# ESP32-C5-LP register map
Vendor: ESPRESSIF SYSTEMS (SHANGHAI) CO., LTD.; Series: ESP32 C-Series; File version: 1
CPU: RV32IMAC r0p0, little endian, no MPU, no FPU, 0 interrupt priority bits
Address unit: 32 bits
Registers are 32-bit, read-write, reset 0x0 unless marked. A register's access mark holds for its fields unless they carry their own. Offsets are from the block's base; [hi:lo] are bit positions.

## LP_I2C0 — Low-power I2C (Inter-Integrated Circuit) Controller 0
Base 0x600B1800
0x00 I2C_SCL_LOW_PERIOD — Configures the low level width of the SCL Clock
  [8:0] I2C_SCL_LOW_PERIOD — This register is used to configure for how long SCL remains low in master mode, in I2C module clock cycles.
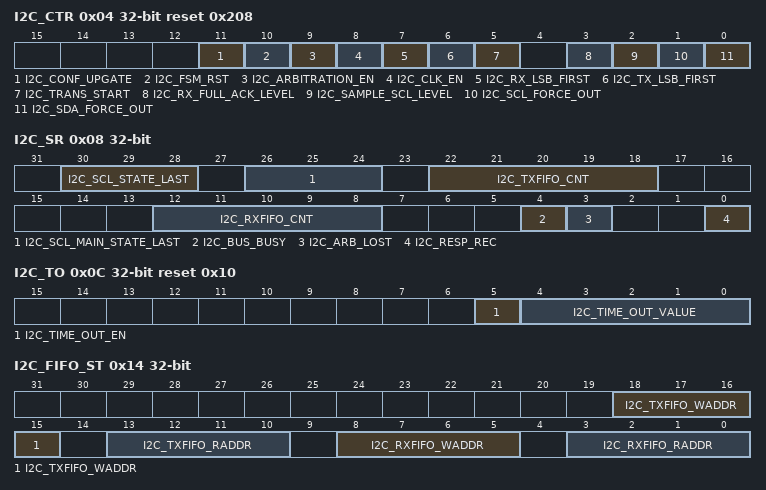
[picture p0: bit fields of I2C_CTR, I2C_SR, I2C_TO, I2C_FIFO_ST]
0x04 I2C_CTR access per field reset 0x208 — Transmission setting
  [11] I2C_CONF_UPGATE wo — synchronization bit
  [10] I2C_FSM_RST wo — This register is used to reset the scl FMS.
  [9] I2C_ARBITRATION_EN rw — This is the enable bit for arbitration_lost.
  [8] I2C_CLK_EN rw — Reserved
  [7] I2C_RX_LSB_FIRST rw — This bit is used to control the storage mode for received data.1: receive data from the least significant bit,0: receive data from the most significant bit.
  [6] I2C_TX_LSB_FIRST rw — This bit is used to control the sending mode for data needing to be sent. 1: send data from the least significant bit,0: send data from the most significant bit.
  [5] I2C_TRANS_START wo — Set this bit to start sending the data in txfifo.
  [3] I2C_RX_FULL_ACK_LEVEL rw — This register is used to configure the ACK value that need to sent by master when the rx_fifo_cnt has reached the threshold.
  [2] I2C_SAMPLE_SCL_LEVEL rw — This register is used to select the sample mode.1: sample SDA data on the SCL low level.0: sample SDA data on the SCL high level.
  [1] I2C_SCL_FORCE_OUT rw — 1: direct output, 0: open drain output.
  [0] I2C_SDA_FORCE_OUT rw — 1: direct output, 0: open drain output.
0x08 I2C_SR ro — Describe I2C work status.
  [30:28] I2C_SCL_STATE_LAST — This field indicates the states of the state machine used to produce SCL.0: Idle, 1: Start, 2: Negative edge, 3: Low, 4: Positive edge, 5: High, 6: Stop
  [26:24] I2C_SCL_MAIN_STATE_LAST — This field indicates the states of the I2C module state machine. 0: Idle, 1: Address shift, 2: ACK address, 3: Rx data, 4: Tx data, 5: Send ACK, 6: Wait ACK
  [22:18] I2C_TXFIFO_CNT — This field stores the amount of received data in RAM.
  [12:8] I2C_RXFIFO_CNT — This field represents the amount of data needed to be sent.
  [4] I2C_BUS_BUSY — 1: the I2C bus is busy transferring data, 0: the I2C bus is in idle state.
  [3] I2C_ARB_LOST — When the I2C controller loses control of SCL line, this register changes to 1.
  [0] I2C_RESP_REC — The received ACK value in master mode or slave mode. 0: ACK, 1: NACK.
0x0C I2C_TO reset 0x10 — Setting time out control for receiving data.
  [5] I2C_TIME_OUT_EN — This is the enable bit for time out control.
  [4:0] I2C_TIME_OUT_VALUE — This register is used to configure the timeout for receiving a data bit in APBclock cycles.
0x14 I2C_FIFO_ST ro — FIFO status register.
  [18:15] I2C_TXFIFO_WADDR — This is the offset address of APB bus writing to txfifo.
  [13:10] I2C_TXFIFO_RADDR — This is the offset address of i2c module reading from txfifo.
  [8:5] I2C_RXFIFO_WADDR — This is the offset address of i2c module receiving data and writing to rxfifo.
  [3:0] I2C_RXFIFO_RADDR — This is the offset address of the APB reading from rxfifo
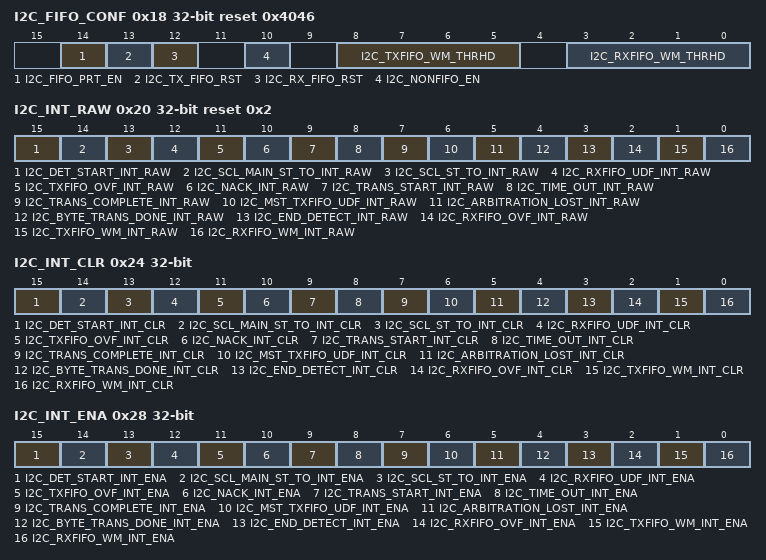
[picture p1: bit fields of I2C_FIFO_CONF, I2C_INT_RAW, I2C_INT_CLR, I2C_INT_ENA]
0x18 I2C_FIFO_CONF reset 0x4046 — FIFO configuration register.
  [14] I2C_FIFO_PRT_EN — The control enable bit of FIFO pointer in non-fifo access mode. This bit controls the valid bits and the interrupts of tx/rx_fifo overflow, underflow, full and empty.
  [13] I2C_TX_FIFO_RST — Set this bit to reset tx-fifo.
  [12] I2C_RX_FIFO_RST — Set this bit to reset rx-fifo.
  [10] I2C_NONFIFO_EN — Set this bit to enable APB nonfifo access.
  [8:5] I2C_TXFIFO_WM_THRHD — The water mark threshold of tx FIFO in nonfifo access mode. When reg_reg_fifo_prt_en is 1 and tx FIFO counter is smaller than reg_txfifo_wm_thrhd[3:0], reg_txfifo_wm_int_raw bit will be valid.
  [3:0] I2C_RXFIFO_WM_THRHD — The water mark threshold of rx FIFO in nonfifo access mode. When reg_reg_fifo_prt_en is 1 and rx FIFO counter is bigger than reg_rxfifo_wm_thrhd[3:0], reg_rxfifo_wm_int_raw bit will be valid.
0x1C I2C_DATA ro — Rx FIFO read data.
  [7:0] I2C_FIFO_RDATA — The value of rx FIFO read data.
0x20 I2C_INT_RAW ro reset 0x2 — Raw interrupt status
  [15] I2C_DET_START_INT_RAW — The raw interrupt bit for I2C_DET_START_INT interrupt.
  [14] I2C_SCL_MAIN_ST_TO_INT_RAW — The raw interrupt bit for I2C_SCL_MAIN_ST_TO_INT interrupt.
  [13] I2C_SCL_ST_TO_INT_RAW — The raw interrupt bit for I2C_SCL_ST_TO_INT interrupt.
  [12] I2C_RXFIFO_UDF_INT_RAW — The raw interrupt bit for I2C_RXFIFO_UDF_INT interrupt.
  [11] I2C_TXFIFO_OVF_INT_RAW — The raw interrupt bit for I2C_TXFIFO_OVF_INT interrupt.
  [10] I2C_NACK_INT_RAW — The raw interrupt bit for I2C_SLAVE_STRETCH_INT interrupt.
  [9] I2C_TRANS_START_INT_RAW — The raw interrupt bit for the I2C_TRANS_START_INT interrupt.
  [8] I2C_TIME_OUT_INT_RAW — The raw interrupt bit for the I2C_TIME_OUT_INT interrupt.
  [7] I2C_TRANS_COMPLETE_INT_RAW — The raw interrupt bit for the I2C_TRANS_COMPLETE_INT interrupt.
  [6] I2C_MST_TXFIFO_UDF_INT_RAW — The raw interrupt bit for I2C_TRANS_COMPLETE_INT interrupt.
  [5] I2C_ARBITRATION_LOST_INT_RAW — The raw interrupt bit for the I2C_ARBITRATION_LOST_INT interrupt.
  [4] I2C_BYTE_TRANS_DONE_INT_RAW — The raw interrupt bit for the I2C_END_DETECT_INT interrupt.
  [3] I2C_END_DETECT_INT_RAW — The raw interrupt bit for the I2C_END_DETECT_INT interrupt.
  [2] I2C_RXFIFO_OVF_INT_RAW — The raw interrupt bit for I2C_RXFIFO_OVF_INT interrupt.
  [1] I2C_TXFIFO_WM_INT_RAW — The raw interrupt bit for I2C_TXFIFO_WM_INT interrupt.
  [0] I2C_RXFIFO_WM_INT_RAW — The raw interrupt bit for I2C_RXFIFO_WM_INT interrupt.
0x24 I2C_INT_CLR wo — Interrupt clear bits
  [15] I2C_DET_START_INT_CLR — Set this bit to clear I2C_DET_START_INT interrupt.
  [14] I2C_SCL_MAIN_ST_TO_INT_CLR — Set this bit to clear I2C_SCL_MAIN_ST_TO_INT interrupt.
  [13] I2C_SCL_ST_TO_INT_CLR — Set this bit to clear I2C_SCL_ST_TO_INT interrupt.
  [12] I2C_RXFIFO_UDF_INT_CLR — Set this bit to clear I2C_RXFIFO_UDF_INT interrupt.
  [11] I2C_TXFIFO_OVF_INT_CLR — Set this bit to clear I2C_TXFIFO_OVF_INT interrupt.
  [10] I2C_NACK_INT_CLR — Set this bit to clear I2C_SLAVE_STRETCH_INT interrupt.
  [9] I2C_TRANS_START_INT_CLR — Set this bit to clear the I2C_TRANS_START_INT interrupt.
  [8] I2C_TIME_OUT_INT_CLR — Set this bit to clear the I2C_TIME_OUT_INT interrupt.
  [7] I2C_TRANS_COMPLETE_INT_CLR — Set this bit to clear the I2C_TRANS_COMPLETE_INT interrupt.
  [6] I2C_MST_TXFIFO_UDF_INT_CLR — Set this bit to clear I2C_TRANS_COMPLETE_INT interrupt.
  [5] I2C_ARBITRATION_LOST_INT_CLR — Set this bit to clear the I2C_ARBITRATION_LOST_INT interrupt.
  [4] I2C_BYTE_TRANS_DONE_INT_CLR — Set this bit to clear the I2C_END_DETECT_INT interrupt.
  [3] I2C_END_DETECT_INT_CLR — Set this bit to clear the I2C_END_DETECT_INT interrupt.
  [2] I2C_RXFIFO_OVF_INT_CLR — Set this bit to clear I2C_RXFIFO_OVF_INT interrupt.
  [1] I2C_TXFIFO_WM_INT_CLR — Set this bit to clear I2C_TXFIFO_WM_INT interrupt.
  [0] I2C_RXFIFO_WM_INT_CLR — Set this bit to clear I2C_RXFIFO_WM_INT interrupt.
0x28 I2C_INT_ENA — Interrupt enable bits
  [15] I2C_DET_START_INT_ENA — The interrupt enable bit for I2C_DET_START_INT interrupt.
  [14] I2C_SCL_MAIN_ST_TO_INT_ENA — The interrupt enable bit for I2C_SCL_MAIN_ST_TO_INT interrupt.
  [13] I2C_SCL_ST_TO_INT_ENA — The interrupt enable bit for I2C_SCL_ST_TO_INT interrupt.
  [12] I2C_RXFIFO_UDF_INT_ENA — The interrupt enable bit for I2C_RXFIFO_UDF_INT interrupt.
  [11] I2C_TXFIFO_OVF_INT_ENA — The interrupt enable bit for I2C_TXFIFO_OVF_INT interrupt.
  [10] I2C_NACK_INT_ENA — The interrupt enable bit for I2C_SLAVE_STRETCH_INT interrupt.
  [9] I2C_TRANS_START_INT_ENA — The interrupt enable bit for the I2C_TRANS_START_INT interrupt.
  [8] I2C_TIME_OUT_INT_ENA — The interrupt enable bit for the I2C_TIME_OUT_INT interrupt.
  [7] I2C_TRANS_COMPLETE_INT_ENA — The interrupt enable bit for the I2C_TRANS_COMPLETE_INT interrupt.
  [6] I2C_MST_TXFIFO_UDF_INT_ENA — The interrupt enable bit for I2C_TRANS_COMPLETE_INT interrupt.
  [5] I2C_ARBITRATION_LOST_INT_ENA — The interrupt enable bit for the I2C_ARBITRATION_LOST_INT interrupt.
  [4] I2C_BYTE_TRANS_DONE_INT_ENA — The interrupt enable bit for the I2C_END_DETECT_INT interrupt.
  [3] I2C_END_DETECT_INT_ENA — The interrupt enable bit for the I2C_END_DETECT_INT interrupt.
  [2] I2C_RXFIFO_OVF_INT_ENA — The interrupt enable bit for I2C_RXFIFO_OVF_INT interrupt.
  [1] I2C_TXFIFO_WM_INT_ENA — The interrupt enable bit for I2C_TXFIFO_WM_INT interrupt.
  [0] I2C_RXFIFO_WM_INT_ENA — The interrupt enable bit for I2C_RXFIFO_WM_INT interrupt.
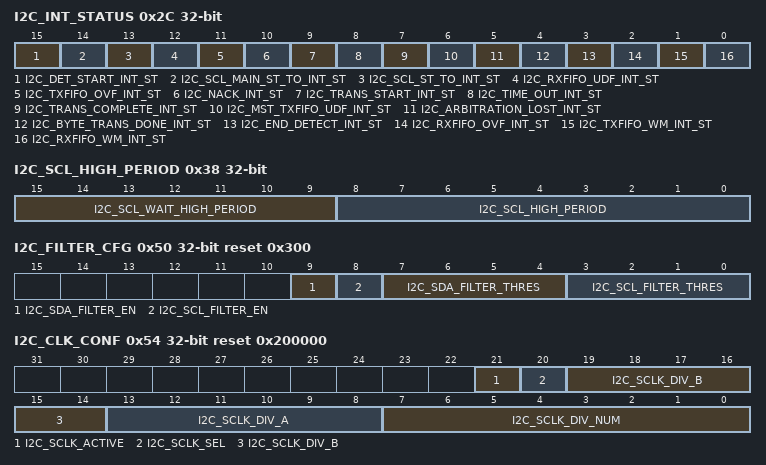
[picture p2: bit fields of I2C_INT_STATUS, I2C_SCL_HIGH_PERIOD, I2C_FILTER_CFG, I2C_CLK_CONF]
0x2C I2C_INT_STATUS ro — Status of captured I2C communication events
  [15] I2C_DET_START_INT_ST — The masked interrupt status bit for I2C_DET_START_INT interrupt.
  [14] I2C_SCL_MAIN_ST_TO_INT_ST — The masked interrupt status bit for I2C_SCL_MAIN_ST_TO_INT interrupt.
  [13] I2C_SCL_ST_TO_INT_ST — The masked interrupt status bit for I2C_SCL_ST_TO_INT interrupt.
  [12] I2C_RXFIFO_UDF_INT_ST — The masked interrupt status bit for I2C_RXFIFO_UDF_INT interrupt.
  [11] I2C_TXFIFO_OVF_INT_ST — The masked interrupt status bit for I2C_TXFIFO_OVF_INT interrupt.
  [10] I2C_NACK_INT_ST — The masked interrupt status bit for I2C_SLAVE_STRETCH_INT interrupt.
  [9] I2C_TRANS_START_INT_ST — The masked interrupt status bit for the I2C_TRANS_START_INT interrupt.
  [8] I2C_TIME_OUT_INT_ST — The masked interrupt status bit for the I2C_TIME_OUT_INT interrupt.
  [7] I2C_TRANS_COMPLETE_INT_ST — The masked interrupt status bit for the I2C_TRANS_COMPLETE_INT interrupt.
  [6] I2C_MST_TXFIFO_UDF_INT_ST — The masked interrupt status bit for I2C_TRANS_COMPLETE_INT interrupt.
  [5] I2C_ARBITRATION_LOST_INT_ST — The masked interrupt status bit for the I2C_ARBITRATION_LOST_INT interrupt.
  [4] I2C_BYTE_TRANS_DONE_INT_ST — The masked interrupt status bit for the I2C_END_DETECT_INT interrupt.
  [3] I2C_END_DETECT_INT_ST — The masked interrupt status bit for the I2C_END_DETECT_INT interrupt.
  [2] I2C_RXFIFO_OVF_INT_ST — The masked interrupt status bit for I2C_RXFIFO_OVF_INT interrupt.
  [1] I2C_TXFIFO_WM_INT_ST — The masked interrupt status bit for I2C_TXFIFO_WM_INT interrupt.
  [0] I2C_RXFIFO_WM_INT_ST — The masked interrupt status bit for I2C_RXFIFO_WM_INT interrupt.
0x30 I2C_SDA_HOLD — Configures the hold time after a negative SCL edge.
  [8:0] TIME — This register is used to configure the time to hold the data after the negativeedge of SCL, in I2C module clock cycles.
0x34 I2C_SDA_SAMPLE — Configures the sample time after a positive SCL edge.
  [8:0] TIME — This register is used to configure for how long SDA is sampled, in I2C module clock cycles.
0x38 I2C_SCL_HIGH_PERIOD — Configures the high level width of SCL
  [15:9] I2C_SCL_WAIT_HIGH_PERIOD — This register is used to configure for the SCL_FSM's waiting period for SCL high level in master mode, in I2C module clock cycles.
  [8:0] I2C_SCL_HIGH_PERIOD — This register is used to configure for how long SCL setup to high level and remains high in master mode, in I2C module clock cycles.
0x40 I2C_SCL_START_HOLD reset 0x8 — Configures the delay between the SDA and SCL negative edge for a start condition
  [8:0] TIME — This register is used to configure the time between the negative edgeof SDA and the negative edge of SCL for a START condition, in I2C module clock cycles.
0x44 I2C_SCL_RSTART_SETUP reset 0x8 — Configures the delay between the positive edge of SCL and the negative edge of SDA
  [8:0] TIME — This register is used to configure the time between the positiveedge of SCL and the negative edge of SDA for a RESTART condition, in I2C module clock cycles.
0x48 I2C_SCL_STOP_HOLD reset 0x8 — Configures the delay after the SCL clock edge for a stop condition
  [8:0] TIME — This register is used to configure the delay after the STOP condition,in I2C module clock cycles.
0x4C I2C_SCL_STOP_SETUP reset 0x8 — Configures the delay between the SDA and SCL positive edge for a stop condition
  [8:0] TIME — This register is used to configure the time between the positive edgeof SCL and the positive edge of SDA, in I2C module clock cycles.
0x50 I2C_FILTER_CFG reset 0x300 — SCL and SDA filter configuration register
  [9] I2C_SDA_FILTER_EN — This is the filter enable bit for SDA.
  [8] I2C_SCL_FILTER_EN — This is the filter enable bit for SCL.
  [7:4] I2C_SDA_FILTER_THRES — When a pulse on the SDA input has smaller width than this register valuein I2C module clock cycles, the I2C controller will ignore that pulse.
  [3:0] I2C_SCL_FILTER_THRES — When a pulse on the SCL input has smaller width than this register valuein I2C module clock cycles, the I2C controller will ignore that pulse.
0x54 I2C_CLK_CONF reset 0x200000 — I2C CLK configuration register
  [21] I2C_SCLK_ACTIVE — The clock switch for i2c module
  [20] I2C_SCLK_SEL — The clock selection for i2c module:0-XTAL,1-CLK_8MHz.
  [19:14] I2C_SCLK_DIV_B — the denominator of the fractional part of the fractional divisor for i2c module
  [13:8] I2C_SCLK_DIV_A — the numerator of the fractional part of the fractional divisor for i2c module
  [7:0] I2C_SCLK_DIV_NUM — the integral part of the fractional divisor for i2c module
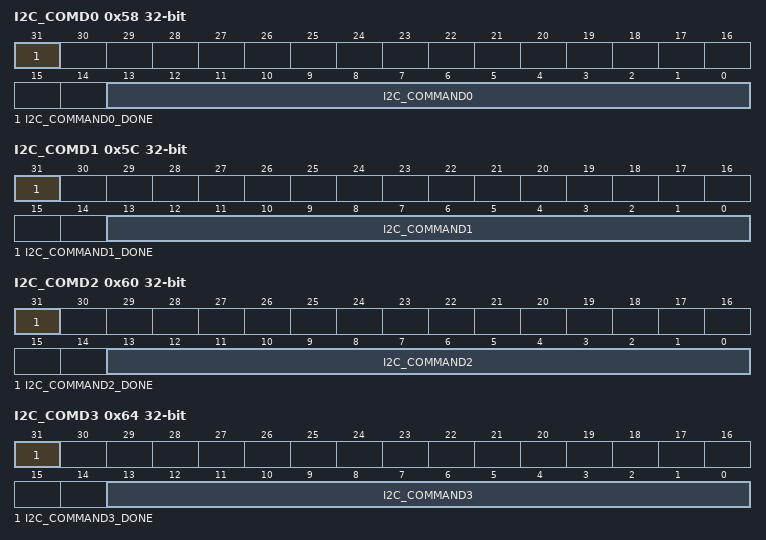
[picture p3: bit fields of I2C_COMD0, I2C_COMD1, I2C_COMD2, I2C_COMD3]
0x58 I2C_COMD0 — I2C command register 0
  [31] I2C_COMMAND0_DONE — When command 0 is done in I2C Master mode, this bit changes to highlevel.
  [13:0] I2C_COMMAND0 — This is the content of command 0. It consists of three parts: op_code is the command, 1: WRITE, 2: STOP, 3: READ, 4: END, 6: RSTART. Byte_num represents the number of bytes that need to be sent or received.ack_check_en, ack_exp and ack are used to control the ACK bit. See I2C cmd structure for moreInformation.
0x5C I2C_COMD1 — I2C command register 1
  [31] I2C_COMMAND1_DONE — When command 1 is done in I2C Master mode, this bit changes to highlevel.
  [13:0] I2C_COMMAND1 — This is the content of command 1. It consists of three parts: op_code is the command, 1: WRITE, 2: STOP, 3: READ, 4: END, 6: RSTART. Byte_num represents the number of bytes that need to be sent or received.ack_check_en, ack_exp and ack are used to control the ACK bit. See I2C cmd structure for moreInformation.
0x60 I2C_COMD2 — I2C command register 2
  [31] I2C_COMMAND2_DONE — When command 2 is done in I2C Master mode, this bit changes to highLevel.
  [13:0] I2C_COMMAND2 — This is the content of command 2. It consists of three parts: op_code is the command, 1: WRITE, 2: STOP, 3: READ, 4: END, 6: RSTART. Byte_num represents the number of bytes that need to be sent or received.ack_check_en, ack_exp and ack are used to control the ACK bit. See I2C cmd structure for moreInformation.
0x64 I2C_COMD3 — I2C command register 3
  [31] I2C_COMMAND3_DONE — When command 3 is done in I2C Master mode, this bit changes to highlevel.
  [13:0] I2C_COMMAND3 — This is the content of command 3. It consists of three parts: op_code is the command, 1: WRITE, 2: STOP, 3: READ, 4: END, 6: RSTART. Byte_num represents the number of bytes that need to be sent or received.ack_check_en, ack_exp and ack are used to control the ACK bit. See I2C cmd structure for moreInformation.
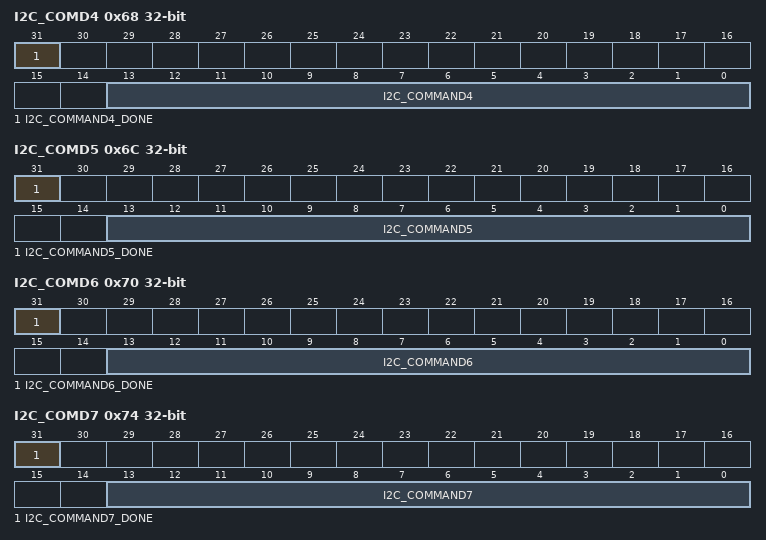
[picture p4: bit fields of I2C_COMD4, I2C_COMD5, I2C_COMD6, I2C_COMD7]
0x68 I2C_COMD4 — I2C command register 4
  [31] I2C_COMMAND4_DONE — When command 4 is done in I2C Master mode, this bit changes to highlevel.
  [13:0] I2C_COMMAND4 — This is the content of command 4. It consists of three parts: op_code is the command, 1: WRITE, 2: STOP, 3: READ, 4: END, 6: RSTART. Byte_num represents the number of bytes that need to be sent or received.ack_check_en, ack_exp and ack are used to control the ACK bit. See I2C cmd structure for moreInformation.
0x6C I2C_COMD5 — I2C command register 5
  [31] I2C_COMMAND5_DONE — When command 5 is done in I2C Master mode, this bit changes to high level.
  [13:0] I2C_COMMAND5 — This is the content of command 5. It consists of three parts:op_code is the command, 1: WRITE, 2: STOP, 3: READ, 4: END, 6: RSTART. Byte_num represents the number of bytes that need to be sent or received.ack_check_en, ack_exp and ack are used to control the ACK bit. See I2C cmd structure for moreInformation.
0x70 I2C_COMD6 — I2C command register 6
  [31] I2C_COMMAND6_DONE — When command 6 is done in I2C Master mode, this bit changes to high level.
  [13:0] I2C_COMMAND6 — This is the content of command 6. It consists of three parts: op_code is the command, 1: WRITE, 2: STOP, 3: READ, 4: END, 6: RSTART. Byte_num represents the number of bytes that need to be sent or received.ack_check_en, ack_exp and ack are used to control the ACK bit. See I2C cmd structure for moreInformation.
0x74 I2C_COMD7 — I2C command register 7
  [31] I2C_COMMAND7_DONE — When command 7 is done in I2C Master mode, this bit changes to high level.
  [13:0] I2C_COMMAND7 — This is the content of command 7. It consists of three parts: op_code is the command, 1: WRITE, 2: STOP, 3: READ, 4: END, 6: RSTART. Byte_num represents the number of bytes that need to be sent or received.ack_check_en, ack_exp and ack are used to control the ACK bit. See I2C cmd structure for moreInformation.
0x78 I2C_SCL_ST_TIME_OUT reset 0x10 — SCL status time out register
  [4:0] I2C_SCL_ST_TO_I2C — The threshold value of SCL_FSM state unchanged period. It should be o more than 23
0x7C I2C_SCL_MAIN_ST_TIME_OUT reset 0x10 — SCL main status time out register
  [4:0] I2C_SCL_MAIN_ST_TO_I2C — The threshold value of SCL_MAIN_FSM state unchanged period.nIt should be o more than 23
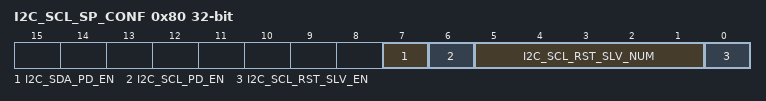
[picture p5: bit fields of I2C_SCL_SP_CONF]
0x80 I2C_SCL_SP_CONF — Power configuration register
  [7] I2C_SDA_PD_EN — The power down enable bit for the I2C output SDA line. 1: Power down. 0: Not power down. Set reg_sda_force_out and reg_sda_pd_en to 1 to stretch SDA low.
  [6] I2C_SCL_PD_EN — The power down enable bit for the I2C output SCL line. 1: Power down. 0: Not power down. Set reg_scl_force_out and reg_scl_pd_en to 1 to stretch SCL low.
  [5:1] I2C_SCL_RST_SLV_NUM — Configure the pulses of SCL generated in I2C master mode. Valid when reg_scl_rst_slv_en is 1.
  [0] I2C_SCL_RST_SLV_EN — When I2C master is IDLE, set this bit to send out SCL pulses. The number of pulses equals to reg_scl_rst_slv_num[4:0].
0xF8 I2C_DATE reset 0x2401040 — Version register
  [31:0] I2C_DATE — This is the the version register.
0x100 I2C_TXFIFO_START_ADDR ro — I2C TXFIFO base address register
  [31:0] I2C_TXFIFO_START_ADDR — This is the I2C txfifo first address.
0x180 I2C_RXFIFO_START_ADDR ro — I2C RXFIFO base address register
  [31:0] I2C_RXFIFO_START_ADDR — This is the I2C rxfifo first address.
